/*
 * The MIT License (MIT)
 *
 * Copyright (c) 2015-2019 Erik Moqvist
 *
 * Permission is hereby granted, free of charge, to any person obtaining a copy
 * of this software and associated documentation files (the "Software"), to deal
 * in the Software without restriction, including without limitation the rights
 * to use, copy, modify, merge, publish, distribute, sublicense, and/or sell
 * copies of the Software, and to permit persons to whom the Software is
 * furnished to do so, subject to the following conditions:
 *
 * The above copyright notice and this permission notice shall be included in all
 * copies or substantial portions of the Software.
 *
 * THE SOFTWARE IS PROVIDED "AS IS", WITHOUT WARRANTY OF ANY KIND, EXPRESS OR
 * IMPLIED, INCLUDING BUT NOT LIMITED TO THE WARRANTIES OF MERCHANTABILITY,
 * FITNESS FOR A PARTICULAR PURPOSE AND NONINFRINGEMENT. IN NO EVENT SHALL THE
 * AUTHORS OR COPYRIGHT HOLDERS BE LIABLE FOR ANY CLAIM, DAMAGES OR OTHER
 * LIABILITY, WHETHER IN AN ACTION OF CONTRACT, TORT OR OTHERWISE, ARISING FROM,
 * OUT OF OR IN CONNECTION WITH THE SOFTWARE OR THE USE OR OTHER DEALINGS IN THE
 * SOFTWARE.
 */

VERSION ""

NS_ :

BS_:

BU_: tx_node
VAL_TABLE_ example_choice 255 "Not available" 254 "Error" ;

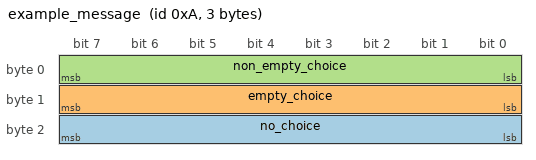
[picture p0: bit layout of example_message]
BO_ 10 example_message: 3 tx_node
 SG_ no_choice : 16|8@1- (1,0) [0|0] "" Vector__XXX
 SG_ empty_choice : 8|8@1- (1,0) [0|0] "" Vector__XXX
 SG_ non_empty_choice : 0|8@1- (1,0) [0|0] "" Vector__XXX

BA_DEF_  "BusType" STRING ;
BA_DEF_DEF_  "BusType" "CAN";
VAL_ 10 non_empty_choice 255 "Not available" 254 "Error" ;
